# RE01_256KB register map
Vendor: Renesas Electronics Corporation; Series: RE01; File version: 1.00.01
CPU: CM0PLUS r0p1, little endian, MPU, no FPU, VTOR, 2 interrupt priority bits, 32 interrupts
Registers are 8-bit, read-write, reset 0x0 unless marked. A register's access mark holds for its fields unless they carry their own. Offsets are from the block's base; [hi:lo] are bit positions; {n}, {i} and the like mark numbered series.

## LST — Low-Speed Clock Timer
Base 0x40084400
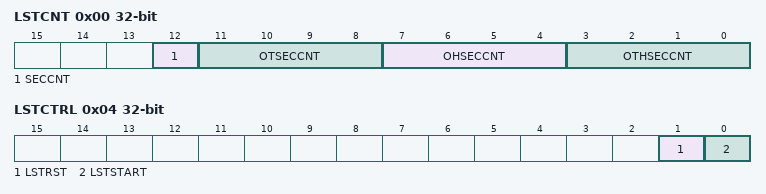
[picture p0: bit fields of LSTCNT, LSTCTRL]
0x00 LSTCNT 32-bit ro — Low-Speed Clock Timer Count Register
  [12] SECCNT — 1-Second Count
  [11:8] OTSECCNT — 0.1-Second Count
  [7:4] OHSECCNT — 0.01-Second Count
  [3:0] OTHSECCNT — 0.001-Second Count
0x04 LSTCTRL 32-bit — Low-Speed Clock Timer Counter Control Register
  [1] LSTRST — Counter Clear
    0=No effect; 1=The low-speed clock timer counter and the LSTCNT register are set to 0
  [0] LSTSTART — Count Start
    0=The count stops; 1=The count starts

## WUPT — Wakeup Timer
Base 0x40084480
{0x0+i} TCM{i} (i=0..3) reset 0xFF — Timer Compare Match Register
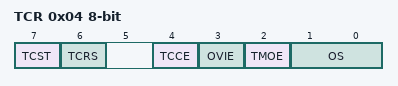
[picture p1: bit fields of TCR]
0x04 TCR — Timer Control Register
  [7] TCST — Timer Count Start
    0=Stop count operation in the TCNT counter; 1=Start count operation in the TCNT counter
  [6] TCRS — Timer Count Reset
    0=The TCNT counter is in normal operation; 1=Reset the value in the TCNT counter
  [4] TCCE — Timer Count Clock Enable
    0=Stop providing the TCNT count clock; 1=Provide the TCNT count clock
  [3] OVIE — Timer Overflow Interrupt Enable
    0=Disable overflow interrupt requests (WUPT_OVI); 1=Enable overflow interrupt requests (WUPT_OVI)
  [2] TMOE — Timer Output Enable
    0=No pulse ouput from the TMWO pin; 1=Pulse ouput from the TMWO pin
  [1:0] OS — Output Select
    0=Low-level output; 1=Low-level output; 2=High-level output; 3=Inverted output (toggled output)

## DIL — Data Inversion and Logic operation
Base 0x40084500
{0x0+4i} IDR{i} (i=0..3) 32-bit — DIL Input Data Registers {i}
{0x10+4i} ODR{i} (i=0..3) 32-bit ro reset 0xFFFFFFFF — DIL Output Data Registers {i}
{0x20+4i} IDR1{i} (i=0..3) 32-bit — DIL Input Data Registers 1{i}
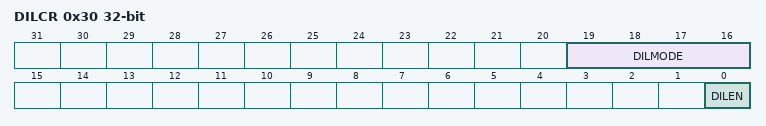
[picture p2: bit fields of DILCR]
0x30 DILCR 32-bit — DIL Control Register
  [19:16] DILMODE — Data Conversion Mode Select
    0=No data conversion; 1=AND operation; 2=OR operation; 3=XOR operation; 8=Byte swap 1; 9=Byte swap 2; 10=Byte swap 3; 11=Bit order inversion every 8 bits; other=Others (Setting prohibited)
  [0] DILEN — Bit Inversion Function Enable
    0=Bit inversion function enabled; 1=Bit inversion function disabled

## DIV — Divider
Base 0x40084600
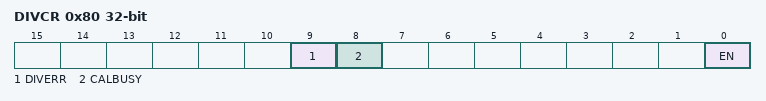
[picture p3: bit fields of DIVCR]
0x80 DIVCR 32-bit — Division Operation Control Register
  [9] DIVERR ro — Division by Zero Flag
    0=The division operation is started after writing any value except 0 to the Divisor Setting Register (DIVSOR); 1=The division operation is started after writing 0 to the Divisor Setting Register (DIVSOR)
  [8] CALBUSY ro — Division Operation Status Flag
    0=Idle (next division operation can be started); 1=Division operation is in progress (next operation cannot be started)
  [0] EN wo — Division Operation Start
    0=No effect; 1=Start a division operation
0x84 DIVIDEND 32-bit — Dividend Setting Register
0x88 DIVSOR 32-bit — Divisor Setting Register
0x8C QUOTIENT 32-bit ro — Quotient Indication Register
0x90 REMAINDER 32-bit ro

## VREF — Reference Voltage Generation Circuit
Base 0x40086A00
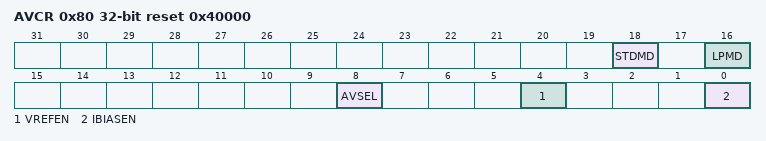
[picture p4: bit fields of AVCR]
0x80 AVCR 32-bit reset 0x40000 — Reference Voltage Output Control Register
  [18] STDMD — Standard Operation Mode
    0=Low power consumption mode; 1=Standard operation mode (initial setting)
  [16] LPMD — Low Power Consumption Mode
    0=Standard operation mode (initial setting); 1=Low power consumption mode
  [8] AVSEL — Output Select
    0=1.25 V output from the AVTRO pin; 1=2.5 V output from the AVTRO pin
  [4] VREFEN — Reference Voltage Generation Circuit Enable
    0=Reference voltage output stop; 1=Reference voltage output start
  [0] IBIASEN — Reference Current Source Enable
    0=Reference current source stop; 1=Reference current source start
